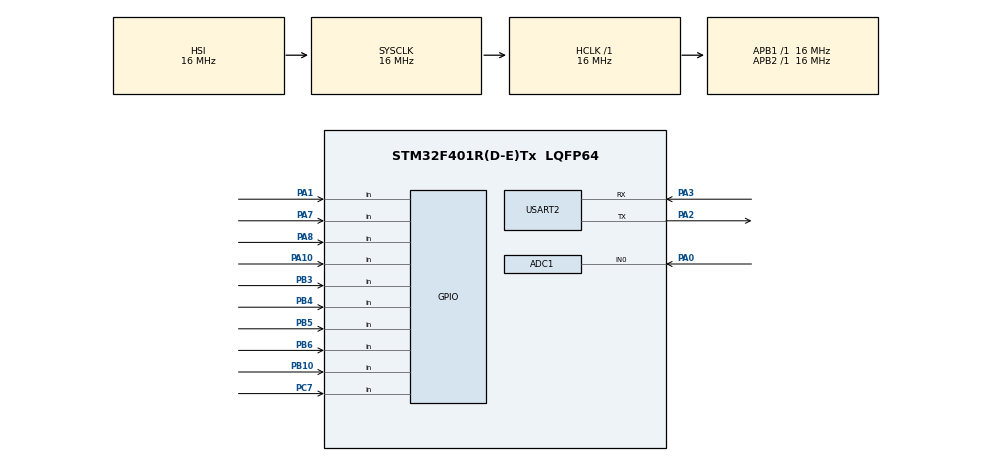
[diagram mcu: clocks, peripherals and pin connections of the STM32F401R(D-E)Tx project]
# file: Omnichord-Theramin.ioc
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ADC1.Channel-0\#ChannelRegularConversion=ADC_CHANNEL_0
ADC1.NbrOfConversionFlag=1
ADC1.Rank-0\#ChannelRegularConversion=1
ADC1.SamplingTime-0\#ChannelRegularConversion=ADC_SAMPLETIME_3CYCLES
ADC1.master=1
Mcu.Family=STM32F4
Mcu.Name=STM32F401R(D-E)Tx
Mcu.Package=LQFP64
NVIC.PriorityGroup=NVIC_PRIORITYGROUP_4
PA0-WKUP.Signal=ADCx_IN0
PA1.GPIO_PuPd=GPIO_PULLUP
PA1.Signal=GPIO_Input
PA10.GPIO_PuPd=GPIO_PULLUP
PA10.Signal=GPIO_Input
PA2.Mode=Asynchronous
PA2.Signal=USART2_TX
PA3.Mode=Asynchronous
PA3.Signal=USART2_RX
PA7.GPIO_PuPd=GPIO_PULLUP
PA7.Signal=GPIO_Input
PA8.GPIO_PuPd=GPIO_PULLUP
PA8.Signal=GPIO_Input
PB10.GPIO_PuPd=GPIO_PULLUP
PB10.Signal=GPIO_Input
PB3.GPIO_PuPd=GPIO_PULLUP
PB3.Signal=GPIO_Input
PB4.GPIO_PuPd=GPIO_PULLUP
PB4.Signal=GPIO_Input
PB5.GPIO_PuPd=GPIO_PULLUP
PB5.Signal=GPIO_Input
PB6.GPIO_PuPd=GPIO_PULLUP
PB6.Signal=GPIO_Input
PC7.GPIO_PuPd=GPIO_PULLUP
PC7.Signal=GPIO_Input
ProjectManager.HeapSize=0x200
ProjectManager.StackSize=0x400
ProjectManager.TargetToolchain=STM32CubeIDE
RCC.AHBFreq_Value=16000000
RCC.APB1Freq_Value=16000000
RCC.APB2Freq_Value=16000000
RCC.CortexFreq_Value=16000000
RCC.HSE_VALUE=25000000
RCC.HSI_VALUE=16000000
RCC.LSE_VALUE=32768
RCC.SYSCLKFreq_VALUE=16000000
RCC.VCOOutputFreq_Value=192000000
SH.ADCx_IN0.0=ADC1_IN0,IN0
USART2.VirtualMode=VM_ASYNC
board=custom

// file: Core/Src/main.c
/* USER CODE BEGIN Header */
/**
  ******************************************************************************
  * @file           : main.c
  * @brief          : Main program body
  ******************************************************************************
  * @attention
  *
  * Copyright (c) 2025 STMicroelectronics.
  * All rights reserved.
  *
  * This software is licensed under terms that can be found in the LICENSE file
  * in the root directory of this software component.
  * If no LICENSE file comes with this software, it is provided AS-IS.
  *
  ******************************************************************************
  */
/* USER CODE END Header */
#include "main.h"

/* USER CODE BEGIN Includes */
#include <string.h>
#include <stdio.h>
/* USER CODE END Includes */

/* USER CODE BEGIN PTD */
#define NUM_CHORD_BTNS 9
/* USER CODE END PTD */

ADC_HandleTypeDef hadc1;

UART_HandleTypeDef huart2;

/* USER CODE BEGIN PV */
// Chord Pins
GPIO_TypeDef *chordPorts[NUM_CHORD_BTNS] = {
    GPIOA,   // D2  PA10 -> Eb
    GPIOB,   // D3  PB3  -> Bb
    GPIOB,   // D4  PB5  -> F
    GPIOB,   // D5  PB4  -> C
    GPIOB,   // D6  PB10 -> G
    GPIOA,   // D7  PA8  -> D
    GPIOA,   // D8  PA9  -> A
    GPIOC,   // D9  PC7  -> E
    GPIOB    // D10 PB6  -> B
};

uint16_t chordPins[NUM_CHORD_BTNS] = {
    GPIO_PIN_10, // PA10
    GPIO_PIN_3,  // PB3
    GPIO_PIN_5,  // PB5
    GPIO_PIN_4,  // PB4
    GPIO_PIN_10, // PB10
    GPIO_PIN_8,  // PA8
    GPIO_PIN_9,  // PA9
    GPIO_PIN_7,  // PC7
    GPIO_PIN_6   // PB6
};

const char *chordNames[NUM_CHORD_BTNS] = {
    "Eb","Bb","F","C","G","D","A","E","B"
};
/* USER CODE END PV */

void SystemClock_Config(void);
static void MX_GPIO_Init(void);
static void MX_ADC1_Init(void);
static void MX_USART2_UART_Init(void);

int main(void)
{

  /* MCU Configuration--------------------------------------------------------*/

  /* Reset of all peripherals, Initializes the Flash interface and the Systick. */
  HAL_Init();

  /* Configure the system clock */
  SystemClock_Config();

  /* Initialize all configured peripherals */
  MX_GPIO_Init();
  MX_ADC1_Init();
  MX_USART2_UART_Init();
  /* USER CODE BEGIN 2 */
  HAL_UART_Transmit(&huart2, (uint8_t*)"OMNICHORD READY\r\n", 17, HAL_MAX_DELAY);
  char txbuf[64];
  /* USER CODE END 2 */

  /* Infinite loop */
  /* USER CODE BEGIN WHILE */
  while (1)
  {
    HAL_ADC_Start(&hadc1);
    HAL_ADC_PollForConversion(&hadc1, HAL_MAX_DELAY);
    uint32_t adcval = HAL_ADC_GetValue(&hadc1);
    HAL_ADC_Stop(&hadc1);

    // scale 0..4095 -> 0..127
    uint8_t thereminVal = (adcval * 127) / 4095;
    sprintf(txbuf, "THEREMIN %u\r\n", thereminVal);
    HAL_UART_Transmit(&huart2, (uint8_t*)txbuf, strlen(txbuf), HAL_MAX_DELAY);

    // minor and 7th
    uint8_t isMinor   = (HAL_GPIO_ReadPin(GPIOA, GPIO_PIN_1) == GPIO_PIN_RESET);
    uint8_t isSeventh = (HAL_GPIO_ReadPin(GPIOA, GPIO_PIN_7) == GPIO_PIN_RESET);

    // scan buttons
    for (int i = 0; i < NUM_CHORD_BTNS; i++)
    {
        if (HAL_GPIO_ReadPin(chordPorts[i], chordPins[i]) == GPIO_PIN_RESET)
        {
            HAL_Delay(10);
            if (HAL_GPIO_ReadPin(chordPorts[i], chordPins[i]) == GPIO_PIN_RESET)
            {
                const char *quality = "MAJ";
                if (isSeventh) quality = "7TH";
                else if (isMinor) quality = "MIN";

                sprintf(txbuf, "CHORD %s %s\r\n", chordNames[i], quality);
                HAL_UART_Transmit(&huart2, (uint8_t*)txbuf, strlen(txbuf), HAL_MAX_DELAY);
                while (HAL_GPIO_ReadPin(chordPorts[i], chordPins[i]) == GPIO_PIN_RESET)
                    HAL_Delay(5);
            }
        }
    }

    HAL_Delay(20);
  }
    /* USER CODE END WHILE */

}

void SystemClock_Config(void)
{
  RCC_OscInitTypeDef RCC_OscInitStruct = {0};
  RCC_ClkInitTypeDef RCC_ClkInitStruct = {0};

  /** Configure the main internal regulator output voltage
  */
  __HAL_RCC_PWR_CLK_ENABLE();
  __HAL_PWR_VOLTAGESCALING_CONFIG(PWR_REGULATOR_VOLTAGE_SCALE2);

  /** Initializes the RCC Oscillators according to the specified parameters
  * in the RCC_OscInitTypeDef structure.
  */
  RCC_OscInitStruct.OscillatorType = RCC_OSCILLATORTYPE_HSI;
  RCC_OscInitStruct.HSIState = RCC_HSI_ON;
  RCC_OscInitStruct.HSICalibrationValue = RCC_HSICALIBRATION_DEFAULT;
  RCC_OscInitStruct.PLL.PLLState = RCC_PLL_NONE;
  if (HAL_RCC_OscConfig(&RCC_OscInitStruct) != HAL_OK)
  {
    Error_Handler();
  }

  /** Initializes the CPU, AHB and APB buses clocks
  */
  RCC_ClkInitStruct.ClockType = RCC_CLOCKTYPE_HCLK|RCC_CLOCKTYPE_SYSCLK
                              |RCC_CLOCKTYPE_PCLK1|RCC_CLOCKTYPE_PCLK2;
  RCC_ClkInitStruct.SYSCLKSource = RCC_SYSCLKSOURCE_HSI;
  RCC_ClkInitStruct.AHBCLKDivider = RCC_SYSCLK_DIV1;
  RCC_ClkInitStruct.APB1CLKDivider = RCC_HCLK_DIV1;
  RCC_ClkInitStruct.APB2CLKDivider = RCC_HCLK_DIV1;

  if (HAL_RCC_ClockConfig(&RCC_ClkInitStruct, FLASH_LATENCY_0) != HAL_OK)
  {
    Error_Handler();
  }
}

static void MX_ADC1_Init(void)
{

  ADC_ChannelConfTypeDef sConfig = {0};

  /** Configure the global features of the ADC (Clock, Resolution, Data Alignment and number of conversion)
  */
  hadc1.Instance = ADC1;
  hadc1.Init.ClockPrescaler = ADC_CLOCK_SYNC_PCLK_DIV2;
  hadc1.Init.Resolution = ADC_RESOLUTION_12B;
  hadc1.Init.ScanConvMode = DISABLE;
  hadc1.Init.ContinuousConvMode = DISABLE;
  hadc1.Init.DiscontinuousConvMode = DISABLE;
  hadc1.Init.ExternalTrigConvEdge = ADC_EXTERNALTRIGCONVEDGE_NONE;
  hadc1.Init.ExternalTrigConv = ADC_SOFTWARE_START;
  hadc1.Init.DataAlign = ADC_DATAALIGN_RIGHT;
  hadc1.Init.NbrOfConversion = 1;
  hadc1.Init.DMAContinuousRequests = DISABLE;
  hadc1.Init.EOCSelection = ADC_EOC_SINGLE_CONV;
  if (HAL_ADC_Init(&hadc1) != HAL_OK)
  {
    Error_Handler();
  }

  /** Configure for the selected ADC regular channel its corresponding rank in the sequencer and its sample time.
  */
  sConfig.Channel = ADC_CHANNEL_0;
  sConfig.Rank = 1;
  sConfig.SamplingTime = ADC_SAMPLETIME_3CYCLES;
  if (HAL_ADC_ConfigChannel(&hadc1, &sConfig) != HAL_OK)
  {
    Error_Handler();
  }

}

static void MX_USART2_UART_Init(void)
{

  huart2.Instance = USART2;
  huart2.Init.BaudRate = 115200;
  huart2.Init.WordLength = UART_WORDLENGTH_8B;
  huart2.Init.StopBits = UART_STOPBITS_1;
  huart2.Init.Parity = UART_PARITY_NONE;
  huart2.Init.Mode = UART_MODE_TX_RX;
  huart2.Init.HwFlowCtl = UART_HWCONTROL_NONE;
  huart2.Init.OverSampling = UART_OVERSAMPLING_16;
  if (HAL_UART_Init(&huart2) != HAL_OK)
  {
    Error_Handler();
  }

}

static void MX_GPIO_Init(void)
{
  GPIO_InitTypeDef GPIO_InitStruct = {0};

  /* GPIO Ports Clock Enable */
  __HAL_RCC_GPIOA_CLK_ENABLE();
  __HAL_RCC_GPIOB_CLK_ENABLE();
  __HAL_RCC_GPIOC_CLK_ENABLE();

  /*Configure GPIO pins : PA1 PA7 PA8 PA9 PA10 */
  GPIO_InitStruct.Pin = GPIO_PIN_1|GPIO_PIN_7|GPIO_PIN_8|GPIO_PIN_9|GPIO_PIN_10;
  GPIO_InitStruct.Mode = GPIO_MODE_INPUT;
  GPIO_InitStruct.Pull = GPIO_PULLUP;
  HAL_GPIO_Init(GPIOA, &GPIO_InitStruct);

  /*Configure GPIO pins : PB10 PB3 PB4 PB5
                           PB6 */
  GPIO_InitStruct.Pin = GPIO_PIN_10|GPIO_PIN_3|GPIO_PIN_4|GPIO_PIN_5
                          |GPIO_PIN_6;
  GPIO_InitStruct.Mode = GPIO_MODE_INPUT;
  GPIO_InitStruct.Pull = GPIO_PULLUP;
  HAL_GPIO_Init(GPIOB, &GPIO_InitStruct);

  /*Configure GPIO pin : PC7 */
  GPIO_InitStruct.Pin = GPIO_PIN_7;
  GPIO_InitStruct.Mode = GPIO_MODE_INPUT;
  GPIO_InitStruct.Pull = GPIO_PULLUP;
  HAL_GPIO_Init(GPIOC, &GPIO_InitStruct);

}

void Error_Handler(void)
{
  __disable_irq();
  while (1)
  {
  }
}
